# ADuCM302x register map
Vendor: Analog Devices; Series: ADuCM302x; File version: 1p0
CPU: CM3 r0p1, little endian, no MPU, no FPU, 3 interrupt priority bits
Registers are 32-bit, read-write, reset 0x0 unless marked. A register's access mark holds for its fields unless they carry their own. Offsets are from the block's base; [hi:lo] are bit positions; {n}, {i} and the like mark numbered series; <NAME> marks a mode.

## PMG0 — Power Management
Base 0x4004C000
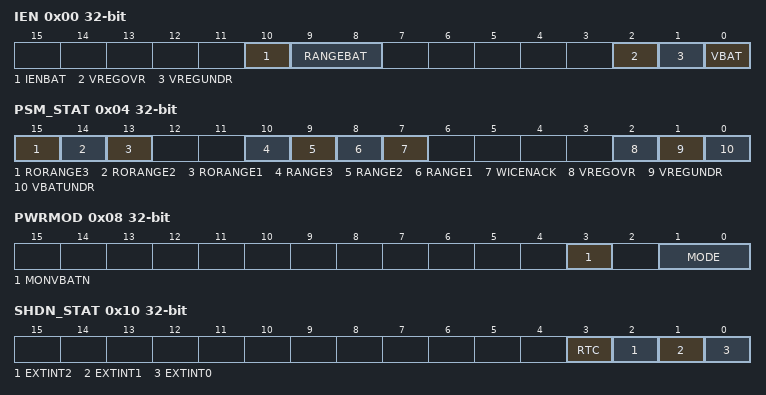
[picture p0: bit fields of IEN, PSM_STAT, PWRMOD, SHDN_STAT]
0x00 IEN — Power Supply Monitor Interrupt Enable
  [10] IENBAT range 0x00000000..0x00000001 — Interrupt enable for VBAT range
  [9:8] RANGEBAT — Battery Monitor Range
    0=region1 (Configure to generate interrupt if VBAT > 2.75 V); 1=region2 (Configure to generate interrupt if VBAT between 2.75 V - 1.6 V); 2=region3 (Configure to generate interrupt if VBAT between 2.3 V - 1.6 V); 3=NA
  [2] VREGOVR range 0x00000000..0x00000001 — Enable Interrupt when VREG over-voltage: over- 1.32 V
  [1] VREGUNDR range 0x00000000..0x00000001 — Enable Interrupt when VREG under-voltage: below 1V
  [0] VBAT range 0x00000000..0x00000001 — Enable Interrupt for VBAT
0x04 PSM_STAT — Power Supply Monitor Status
  [15] RORANGE3 ro — VBAT range3 (2.3 V - 1.6 V)
  [14] RORANGE2 ro — VBAT range2 (2.75 V - 2.3 V)
  [13] RORANGE1 ro — VBAT range1 (> 2.75 V)
    0=batstat1 (VBAT not in the range specified); 1=batstat0 (VBAT in the range specified)
  [10] RANGE3 — VBAT range3 (2.3 V - 1.6 V)
  [9] RANGE2 — VBAT range2 (2.75 V - 2.3 V)
  [8] RANGE1 — VBAT range1 (> 2.75 V)
  [7] WICENACK ro — WIC Enable Acknowledge from Cortex
  [2] VREGOVR range 0x00000000..0x00000001 — Status bit for alarm indicating Overvoltage for VREG
  [1] VREGUNDR range 0x00000000..0x00000001 — Status bit for Alarm indicating VREG is below 1 V
  [0] VBATUNDR range 0x00000000..0x00000001 — Status bit indicating an Alarm that battery is below 1.8 V
0x08 PWRMOD — Power Mode Register
  [3] MONVBATN range 0x00000000..0x00000001 — Monitor VBAT during HIBERNATE Mode. Monitors VBAT by default
  [1:0] MODE — Power Mode Bits
    0=FLEXI (Flexi Mode); 2=HIBERNATE (Hibernate Mode); 3=SHUTDOWN (Shutdown Mode)
0x0C PWRKEY — Key Protection for PWRMOD and SRAMRET
  [15:0] VALUE wo range 0x00000000..0x0000FFFF — Power control key register
0x10 SHDN_STAT — Shutdown Status Register
  [3] RTC ro — Wake-up by Interrupt from RTC
  [2] EXTINT2 ro — Wake-up by Interrupt from External Interrupt 2
  [1] EXTINT1 ro — Wake-up by Interrupt from External Interrupt 1
  [0] EXTINT0 ro — Wake-up by Interrupt from External Interrupt 0
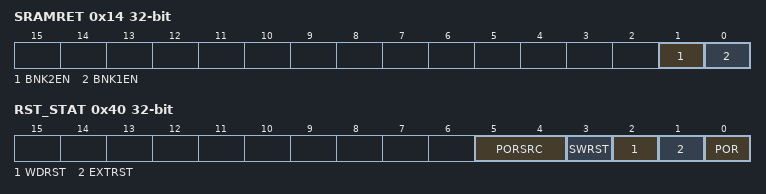
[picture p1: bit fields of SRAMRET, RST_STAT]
0x14 SRAMRET — Control for Retention SRAM during HIBERNATE Mode
  [1] BNK2EN range 0x00000000..0x00000001 — Enable retention bank 2 (16 KB)
  [0] BNK1EN range 0x00000000..0x00000001 — Enable retention bank 1 (8 KB)
0x40 RST_STAT — Reset status
  [5:4] PORSRC ro — Power-on-Reset Source
    0=FAILSAFE_HV (POR triggered because VBAT drops below Fail Safe); 1=RST_VBAT (POR trigger because VBAT supply (VBAT < 1.7 V)); 2=RST_VREG (POR triggered because VDD supply (VDD < 1.08 V)); 3=FAILSAFE_LV (POR triggered because VREG drops below Fail Safe)
  [3] SWRST range 0x00000000..0x00000001 — Software reset
  [2] WDRST range 0x00000000..0x00000001 — Watchdog Time-out Reset
  [1] EXTRST range 0x00000000..0x00000001 — External reset
  [0] POR range 0x00000000..0x00000001 — Power-on-Reset
0x44 CTL1 reset 0xA00000 — HPBUCK Control
  [0] HPBUCKEN range 0x00000000..0x00000001 — Enable HP Buck

## XINT0 — External interrupt configuration
Base 0x4004C080
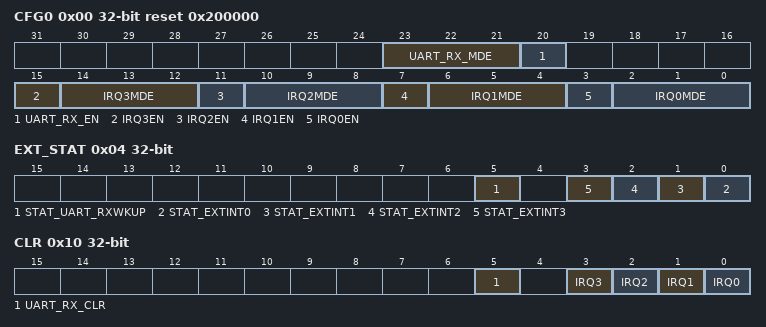
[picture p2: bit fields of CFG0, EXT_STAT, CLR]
0x00 CFG0 reset 0x200000 — External Interrupt Configuration
  [23:21] UART_RX_MDE — External Interrupt using UART_RX wakeup Mode registers
  [20] UART_RX_EN — External Interrupt enable bit
  [15] IRQ3EN — External Interrupt 3 enable bit
  [4n+2:4n] IRQ{n}MDE (n=0..3) — External Interrupt {n} Mode registers
  [11] IRQ2EN — External Interrupt 2 Enable bit
  [7] IRQ1EN — External Interrupt 1 Enable bit
  [3] IRQ0EN — External Interrupt 0 Enable bit
0x04 EXT_STAT — External Wakeup Interrupt Status
  [5] STAT_UART_RXWKUP ro — Interrupt status bit for UART RX wakeup interrupt
  [n] STAT_EXTINT{n} ro (n=0..3) — Interrupt status bit for External Interrupt {n}
0x10 CLR — External Interrupt Clear
  [5] UART_RX_CLR range 0x00000000..0x00000001 — External interrupt Clear for UART_RX WAKEUP interrupt
  [n] IRQ{n} range 0x00000000..0x00000001 (n=0..3) — External interrupt {n}
0x14 NMICLR — Non-Maskable Interrupt Clear
  [0] CLR range 0x00000000..0x00000001 — NMI clear
